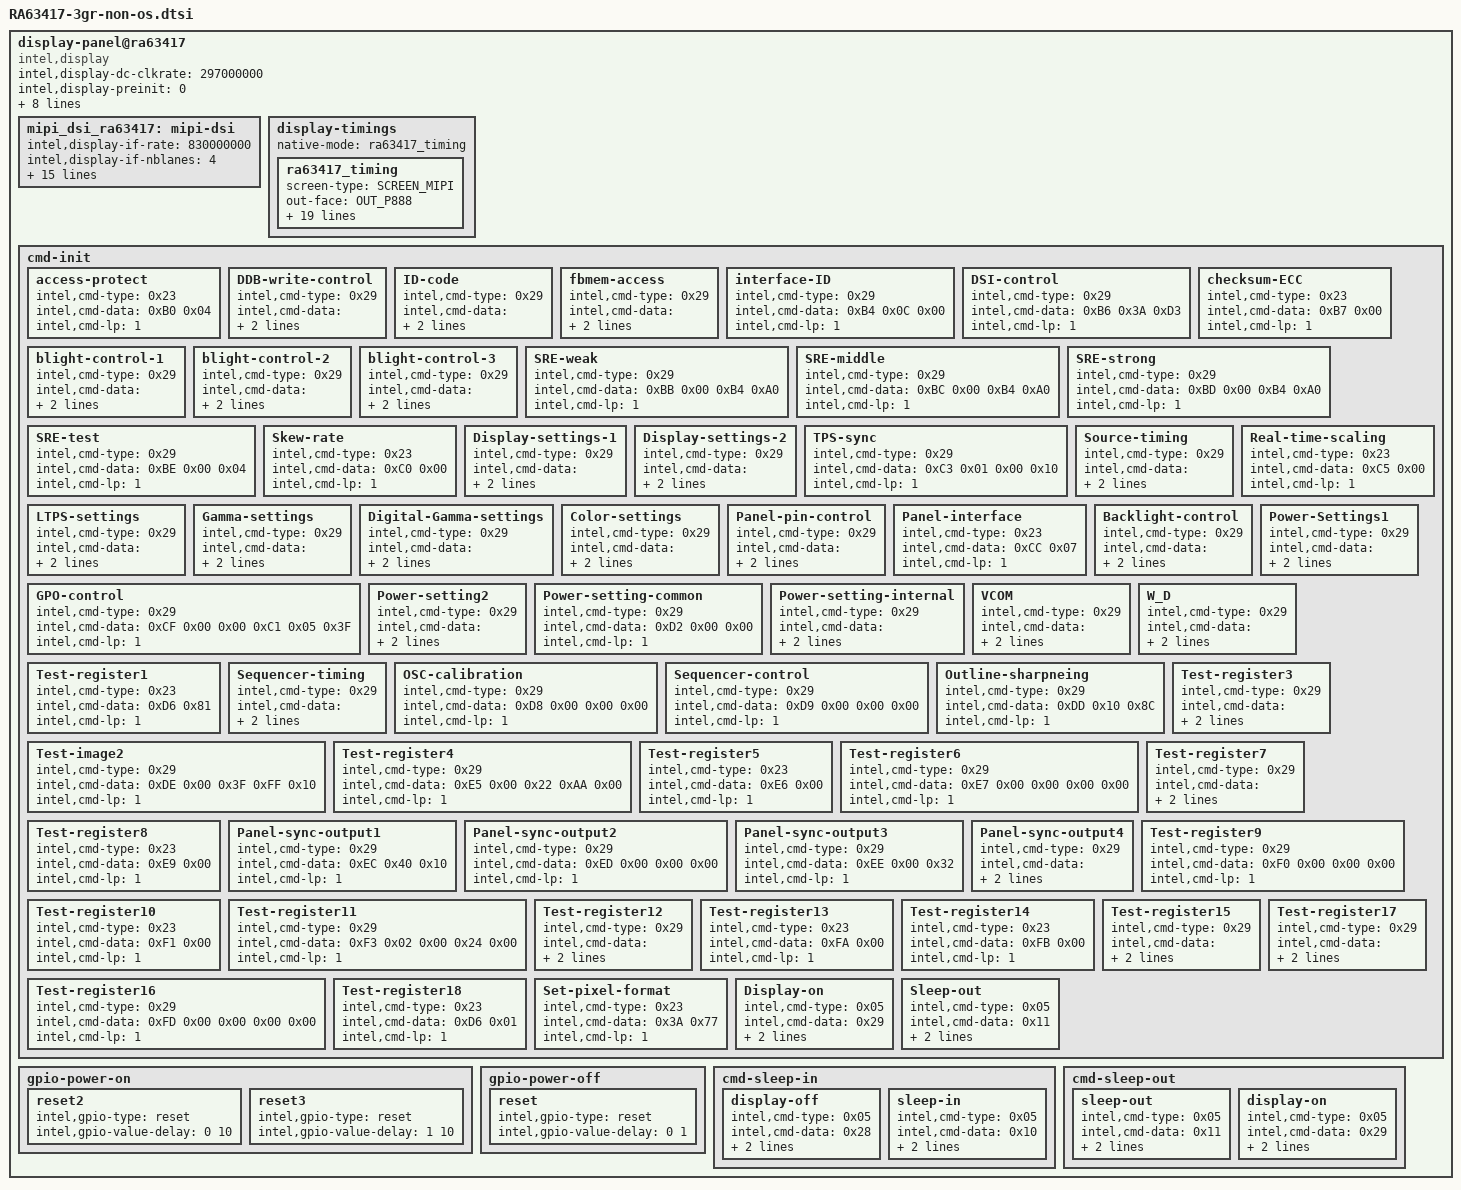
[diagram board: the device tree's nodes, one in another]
/*
 * definition at "include/dt-bindings/sofiafb/sofia_fb.h"
 */

display-panel@ra63417 {
	compatible = "intel,display";
	intel,display-dc-clkrate = <297000000>;
	intel,display-preinit = <0>;
	intel,display-ramless = <1>;
	intel,display-fps = <60>;
	intel,display-vid-mode = "events";
	intel,display-vid-id = <0>;
	intel,display-eot = <1>;
	intel,display-gate = <1>;
	intel,display-if-dts = <1>;
	intel,display-if = <&mipi_dsi_ra63417>;
	mipi_dsi_ra63417:mipi-dsi {
		intel,display-if-rate = <830000000>;
		intel,display-if-nblanes = <4>;
		intel,display-if-phy-pwup = <6>;
		intel,display-if-phy-calib = <3>;
		intel,display-if-phy-to_lp_hs_req = <24>;
		intel,display-if-phy-to_lp_hs_dis = <25>;
		intel,display-if-phy-to_lp_hs_eot = <60>;
		intel,display-if-phy-to_hs_zero = <15>;
		intel,display-if-phy-to_hs_flip = <24>;
		intel,display-if-phy-lp_clk_div = <31>;
		intel,display-if-phy-to_hs_clk_pre = <36>;
		intel,display-if-phy-to_hs_clk_post = <42>;
		intel,display-if-phy-data_delay = <7>;
		intel,display-if-phy-clock_delay = <7>;
		intel,display-if-phy-lp_tx_tfall = <2>;
		intel,display-if-phy-lp_tx_rise = <2>;
		intel,display-if-phy-lp_tx_vref = <31>;
	};

	display-timings {
		native-mode = <&ra63417_timing>;
		ra63417_timing: ra63417_timing {
			screen-type = <SCREEN_MIPI>;
			out-face    = <OUT_P888>;
			color-mode = <COLOR_RGB>;
			width = <75>;
			height = <132>;
			clock-frequency = <135766800>;
			hactive = <1080>;
			vactive = <1920>;
			hback-porch = <30>;
			hfront-porch = <50>;
			vback-porch = <3>;
			vfront-porch = <8>;
			hsync-len = <10>;
			vsync-len = <3>;
			hsync-active = <0>;
			vsync-active = <0>;
			de-active = <0>;
			pixelclk-active = <0>;
			swap-rb = <0>;
			swap-rg = <0>;
			swap-gb = <0>;
		};
	};

		cmd-init {
			access-protect {
				intel,cmd-type = <0x23>;
				intel,cmd-data = <0xB0 0x04>;
				intel,cmd-lp = <1>;
			};
			DDB-write-control {
				intel,cmd-type = <0x29>;
				intel,cmd-data =<0xE1 0x03 0x00 0x00 0x01 0x02 0x03 0x00 0x00 0x00 0x00>;
				intel,cmd-lp = <1>;
			};
			ID-code {
				intel,cmd-type = <0x29>;
				intel,cmd-data = <0xE2 0x01 0x00 0x00 0x01 0x02 0x03>;
				intel,cmd-lp = <1>;
			};
			fbmem-access {
				intel,cmd-type = <0x29>;
				intel,cmd-data = <0xB3 0x1C 0x00 0x00 0x00 0x00 0x00>;
				intel,cmd-lp = <1>;
			};
			interface-ID {
				intel,cmd-type = <0x29>;
				intel,cmd-data = <0xB4 0x0C 0x00>;
				intel,cmd-lp = <1>;
			};
			DSI-control {
				intel,cmd-type = <0x29>;
				intel,cmd-data = <0xB6 0x3A 0xD3>;
				intel,cmd-lp = <1>;
			};
			checksum-ECC {
				intel,cmd-type = <0x23>;
				intel,cmd-data = <0xB7 0x00>;
				intel,cmd-lp = <1>;
			};
			blight-control-1 {
				intel,cmd-type = <0x29>;
				intel,cmd-data = <0xB8 0x07 0x90 0x1E 0x10 0x1E 0x32>;
				intel,cmd-lp = <1>;
            };
            blight-control-2 {
                intel,cmd-type = <0x29>;
                intel,cmd-data = <0xB9 0x07 0x82 0x3C 0x10 0x3C 0x87>;
                intel,cmd-lp = <1>;
            };
			blight-control-3 {
				intel,cmd-type = <0x29>;
				intel,cmd-data = <0xBA 0x07 0x78 0x64 0x10 0x64 0xB4>;
				intel,cmd-lp = <1>;
			};
			SRE-weak {
				intel,cmd-type = <0x29>;
				intel,cmd-data = <0xBB 0x00 0xB4 0xA0>;
				intel,cmd-lp = <1>;
			};
			SRE-middle {
				intel,cmd-type = <0x29>;
				intel,cmd-data = <0xBC 0x00 0xB4 0xA0>;
				intel,cmd-lp = <1>;
			};
			SRE-strong {
				intel,cmd-type = <0x29>;
				intel,cmd-data = <0xBD 0x00 0xB4 0xA0>;
				intel,cmd-lp = <1>;
			};
			SRE-test {
				intel,cmd-type = <0x29>;
				intel,cmd-data = <0xBE 0x00 0x04>;
				intel,cmd-lp = <1>;
			};
			Skew-rate {
				intel,cmd-type = <0x23>;
				intel,cmd-data = <0xC0 0x00>;
				intel,cmd-lp = <1>;
			};
			Display-settings-1 {
				intel,cmd-type = <0x29>;
				intel,cmd-data = <0xC1 0x04 0x60 0x00 0xA0 0x04 0x71 0x00 0x00 0x00 0xA8 0xC5 0xD4 0x62 0x6C 0x29 0xB6 0x14 0x00 0x00 0x80 0x23 0x42 0x01 0x00 0x00 0x00 0x00 0x00 0x02 0x00 0x00 0x22 0x00 0x01>;
				intel,cmd-lp = <1>;
			};
			Display-settings-2 {
				intel,cmd-type = <0x29>;
				intel,cmd-data = <0xC2 0x31 0xF7 0x82 0x05 0x03 0x00 0x00>;
				intel,cmd-lp = <1>;
			};
			TPS-sync {
				intel,cmd-type = <0x29>;
				intel,cmd-data = <0xC3 0x01 0x00 0x10>;
				intel,cmd-lp = <1>;
			};
			Source-timing {
				intel,cmd-type = <0x29>;
				intel,cmd-data = <0xC4 0x70 0x00 0x00 0x00 0x00 0x00 0x00 0x00 0x00 0x00 0x02 0x00 0x00 0x00 0x00 0x00 0x00 0x00 0x00 0x00 0x00 0x02>;
				intel,cmd-lp = <1>;
			};
			Real-time-scaling {
				intel,cmd-type = <0x23>;
				intel,cmd-data = <0xC5 0x00>;
				intel,cmd-lp = <1>;
			};
			LTPS-settings {
				intel,cmd-type = <0x29>;
				intel,cmd-data = <0xC6 0x73 0x00 0x44 0x05 0x68 0x00 0x00 0x00 0x00 0x00 0x00 0x00 0x00 0x00 0x00 0x00 0x00 0x0A 0x1A 0x05 0x73 0x00 0x44 0x05 0x68 0x00 0x00 0x00 0x00 0x00 0x00 0x00 0x00 0x00 0x00 0x00 0x00 0x0A 0x1A 0x05>;
				intel,cmd-lp = <1>;
			};
			Gamma-settings {
				intel,cmd-type = <0x29>;
				intel,cmd-data = <0xC7 0x00 0x12 0x1A 0x22 0x30 0x3E 0x4A 0x5A 0x40 0x48 0x54 0x61 0x6A 0x71 0x7F 0x00 0x12 0x1A 0x22 0x30 0x3E 0x4A 0x5A 0x40 0x48 0x54 0x61 0x6A 0x71 0x7F>;
				intel,cmd-lp = <1>;
			};
			Digital-Gamma-settings {
				intel,cmd-type = <0x29>;
				intel,cmd-data = <0xC8 0x01 0x00 0xFC 0x00 0x00 0xE6 0xF0 0x00 0x00 0xFA 0xFE 0xF0 0x0F 0x00 0xFF 0x00 0x00 0xFC 0x0D>;
				intel,cmd-lp = <1>;
			};
			Color-settings {
				intel,cmd-type = <0x29>;
				intel,cmd-data = <0xCA 0x00 0x80 0x80 0x80 0x80 0x80 0x80 0x80 0x08 0x20 0x80 0x80 0x0A 0x4A 0x37 0xA0 0x55 0xF8 0x0C 0x0C 0x20 0x10 0x3F 0x3F 0x00 0x00 0x10 0x10 0x3F 0x3F 0x3F 0x3F>;
				intel,cmd-lp = <1>;
			};
			Panel-pin-control {
				intel,cmd-type = <0x29>;
				intel,cmd-data = <0xCB 0x1F 0xFC 0x3F 0xF8 0x02 0xE0 0x07 0x40 0xC0>;
				intel,cmd-lp = <1>;
			};
			Panel-interface {
				intel,cmd-type = <0x23>;
				intel,cmd-data = <0xCC 0x07>;
				intel,cmd-lp = <1>;
			};
			Backlight-control {
				intel,cmd-type = <0x29>;
				intel,cmd-data = <0xCE 0x75 0x40 0x43 0x49 0x55 0x62 0x71 0x82 0x94 0xA8 0xB9 0xCB 0xDB 0xE9 0xF5 0xFC 0xFF 0x02 0x38 0x04 0x04 0x44 0x60>;
				intel,cmd-lp = <1>;
			};
			GPO-control {
				intel,cmd-type = <0x29>;
				intel,cmd-data = <0xCF 0x00 0x00 0xC1 0x05 0x3F>;
				intel,cmd-lp = <1>;
			};
			Power-Settings1 {
				intel,cmd-type = <0x29>;
				intel,cmd-data = <0xD0 0x11 0x81 0xBB 0x16 0x8F 0x4C 0x19 0x19 0x0C 0x00>;
				intel,cmd-lp = <1>;
			};
			Power-setting2{
				intel,cmd-type = <0x29>;
				intel,cmd-data = <0xD1 0x20 0x00 0x00 0x04 0x08 0x0C 0x10 0x00 0x00 0x00 0x00 0x00 0x3C 0x04 0x20 0x00 0x00 0x04 0x08 0x0C 0x10 0x00 0x00 0x3C 0xC6 0xF0>;
				intel,cmd-lp = <1>;
			};
			Power-setting-common {
				intel,cmd-type = <0x29>;
				intel,cmd-data = <0xD2 0x00 0x00>;
				intel,cmd-lp = <1>;
			};
			Power-setting-internal {
				intel,cmd-type = <0x29>;
				intel,cmd-data = <0xD3 0x1B 0x33 0xBB 0xBB 0xB3 0x33 0x33 0x33 0x00 0x01 0x00 0xA0 0xB8 0xA0 0x02 0x37 0x37 0x33 0x3B 0x37 0x72 0x07 0x3D 0xBF 0x00>;
				intel,cmd-lp = <1>;
			};
			VCOM {
				intel,cmd-type = <0x29>;
				intel,cmd-data = <0xD5 0x06 0x00 0x00 0x01 0x38 0x01 0x38>;
				intel,cmd-lp = <1>;
			};
			W_D {
				intel,cmd-type = <0x29>;
				intel,cmd-data = <0xD5 0x06 0x00 0x00 0x01 0x38 0x01 0x38>;
				intel,cmd-lp = <1>;
			};
			Test-register1 {
				intel,cmd-type = <0x23>;
				intel,cmd-data = <0xD6 0x81>;
				intel,cmd-lp = <1>;
			};
			Sequencer-timing {
				intel,cmd-type = <0x29>;
				intel,cmd-data = <0xD7 0x84 0xFC 0x7F 0xA8 0xCE 0x38 0xFC 0xC1 0x1E 0xE7 0x8F 0x1F 0x3C 0x10 0xFA 0xC3 0x0F 0x04 0x41 0x20 0x00 0x00>;
				intel,cmd-lp = <1>;
			};
			OSC-calibration {
				intel,cmd-type = <0x29>;
				intel,cmd-data = <0xD8 0x00 0x00 0x00>;
				intel,cmd-lp = <1>;
			};
			Sequencer-control {
				intel,cmd-type = <0x29>;
				intel,cmd-data = <0xD9 0x00 0x00 0x00>;
				intel,cmd-lp = <1>;
			};
			Outline-sharpneing {
				intel,cmd-type = <0x29>;
				intel,cmd-data = <0xDD 0x10 0x8C>;
				intel,cmd-lp = <1>;
			};
			Test-image2  {
				intel,cmd-type = <0x29>;
				intel,cmd-data = <0xDE 0x00 0x3F 0xFF 0x10>;
				intel,cmd-lp = <1>;
			};
			Test-register3 {
				intel,cmd-type = <0x29>;
				intel,cmd-data = <0xE4 0x00 0x00 0x00 0x00 0x00 0x00 0x44 0x00 0x00 0x00 0x80 0x00 0x00 0x00 0x00 0x00 0x00 0x00 0x00 0x00 0x00 0x00 0x00 0x00 0x00 0x00 0x00 0x00 0x00 0x00 0x00 0x00 0x00 0x00 0x00 0x00 0x00 0x00 0x00 0x00 0x00>;
				intel,cmd-lp = <1>;
			};
			Test-register4 {
				intel,cmd-type = <0x29>;
				intel,cmd-data = <0xE5 0x00 0x22 0xAA 0x00>;
				intel,cmd-lp = <1>;
			};
			Test-register5 {
				intel,cmd-type = <0x23>;
				intel,cmd-data = <0xE6 0x00>;
				intel,cmd-lp = <1>;
			};
			Test-register6 {
				intel,cmd-type = <0x29>;
				intel,cmd-data = <0xE7 0x00 0x00 0x00 0x00>;
				intel,cmd-lp = <1>;
			};
			Test-register7 {
				intel,cmd-type = <0x29>;
				intel,cmd-data = <0xE8 0x00 0x00 0x00 0x00 0x00 0x00 0x00 0x00 0x00 0x00 0x00>;
				intel,cmd-lp = <1>;
			};
			Test-register8 {
				intel,cmd-type = <0x23>;
				intel,cmd-data = <0xE9 0x00>;
				intel,cmd-lp = <1>;
			};
			Panel-sync-output1 {
				intel,cmd-type = <0x29>;
				intel,cmd-data = <0xEC 0x40 0x10>;
				intel,cmd-lp = <1>;
			};
			Panel-sync-output2 {
				intel,cmd-type = <0x29>;
				intel,cmd-data = <0xED 0x00 0x00 0x00>;
				intel,cmd-lp = <1>;
			};
			Panel-sync-output3 {
				intel,cmd-type = <0x29>;
				intel,cmd-data = <0xEE 0x00 0x32>;
				intel,cmd-lp = <1>;
			};
			Panel-sync-output4 {
				intel,cmd-type = <0x29>;
				intel,cmd-data = <0xEF 0x00 0x00 0x00 0x00 0x00 0x00 0x00 0x00 0x00 0x00>;
				intel,cmd-lp = <1>;
			};
			Test-register9 {
				intel,cmd-type = <0x29>;
				intel,cmd-data = <0xF0 0x00 0x00 0x00>;
				intel,cmd-lp = <1>;
			};
			Test-register10 {
				intel,cmd-type = <0x23>;
				intel,cmd-data = <0xF1 0x00>;
				intel,cmd-lp = <1>;
			};
			Test-register11 {
				intel,cmd-type = <0x29>;
				intel,cmd-data = <0xF3 0x02 0x00 0x24 0x00>;
				intel,cmd-lp = <1>;
			};
			Test-register12 {
				intel,cmd-type = <0x29>;
				intel,cmd-data = <0xF9 0x00 0x3F 0xE0 0x00 0x00 0x07 0xFF 0x00 0x00 0x07 0xFF>;
				intel,cmd-lp = <1>;
			};
			Test-register13 {
				intel,cmd-type = <0x23>;
				intel,cmd-data = <0xFA 0x00>;
				intel,cmd-lp = <1>;
			};
			Test-register14 {
				intel,cmd-type = <0x23>;
				intel,cmd-data = <0xFB 0x00>;
				intel,cmd-lp = <1>;
			};
			Test-register15 {
				intel,cmd-type = <0x29>;
				intel,cmd-data = <0xFC 0x00 0x00 0x00 0x00 0x00 0x00 0x00>;
				intel,cmd-lp = <1>;
			};
			Test-register16 {
				intel,cmd-type = <0x29>;
				intel,cmd-data = <0xFD 0x00 0x00 0x00 0x00>;
				intel,cmd-lp = <1>;
			};
			Test-register17 {
				intel,cmd-type = <0x29>;
				intel,cmd-data = <0xFE 0x00 0x04 0x0D 0x00 0x00 0x30 0x00 0x00>;
				intel,cmd-lp = <1>;
			};
			Test-register18 {
				intel,cmd-type = <0x23>;
				intel,cmd-data = <0xD6 0x01>;
				intel,cmd-lp = <1>;
			};

			Set-pixel-format {
				intel,cmd-type = <0x23>;
				intel,cmd-data = <0x3A 0x77>;
				intel,cmd-lp = <1>;
			};
			Display-on {
				intel,cmd-type = <0x05>;
				intel,cmd-data = <0x29>;
                intel,cmd-delay = <20>;
				intel,cmd-lp = <1>;
			};
			Sleep-out {
				intel,cmd-type = <0x05>;
				intel,cmd-data = <0x11>;
                intel,cmd-delay = <200>;
				intel,cmd-lp = <1>;
			};

		};
		gpio-power-on {
			/*power_en {
				intel,gpio-type = "vhigh";
				intel,gpio-value-delay = <1 41>;
			};*/
/*			reset1 {
				intel,gpio-type = "reset";
				intel,gpio-value-delay = <1 10>;
			};
*/			reset2 {
				intel,gpio-type = "reset";
				intel,gpio-value-delay = <0 10>;
			};
			reset3 {
				intel,gpio-type = "reset";
				intel,gpio-value-delay = <1 10>;
			};
		};

		gpio-power-off {
			reset {
				intel,gpio-type = "reset";
				intel,gpio-value-delay = <0 1>;
			};
			/*power_en {
				intel,gpio-type = "vhigh";
				intel,gpio-value-delay = <0 0>;
			};*/
		};

		cmd-sleep-in {
			display-off {
				intel,cmd-type = <0x05>;
				intel,cmd-data = <0x28>;
				intel,cmd-delay = <200>;
				intel,cmd-lp = <1>;
			};
			sleep-in {
				intel,cmd-type = <0x05>;
				intel,cmd-data = <0x10>;
				intel,cmd-delay = <200>;
				intel,cmd-lp = <1>;
			};
		};

		cmd-sleep-out {
			sleep-out {
				intel,cmd-type = <0x05>;
				intel,cmd-data = <0x11>;
				intel,cmd-delay = <200>;
				intel,cmd-lp = <1>;
			};
			display-on {
				intel,cmd-type = <0x05>;
				intel,cmd-data = <0x29>;
				intel,cmd-delay = <20>;
				intel,cmd-lp = <1>;
			};
		};

	};
